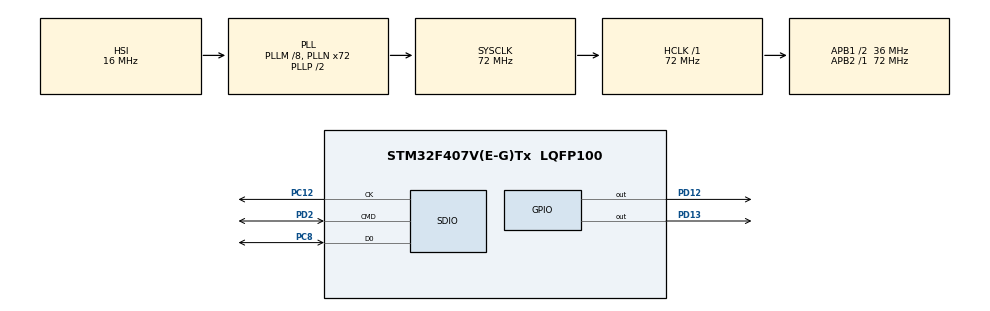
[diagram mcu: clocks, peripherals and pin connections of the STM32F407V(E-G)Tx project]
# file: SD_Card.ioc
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FATFS._MAX_SS=4096
Mcu.Family=STM32F4
Mcu.Name=STM32F407V(E-G)Tx
Mcu.Package=LQFP100
NVIC.PriorityGroup=NVIC_PRIORITYGROUP_0
PC12.Mode=SD_1_bit
PC12.Signal=SDIO_CK
PC8.Mode=SD_1_bit
PC8.Signal=SDIO_D0
PD12.Signal=GPIO_Output
PD13.Signal=GPIO_Output
PD2.Mode=SD_1_bit
PD2.Signal=SDIO_CMD
ProjectManager.HeapSize=0x200
ProjectManager.StackSize=0x400
ProjectManager.TargetToolchain=STM32CubeIDE
RCC.48MHZClocksFreq_Value=48000000
RCC.AHBFreq_Value=72000000
RCC.APB1CLKDivider=RCC_HCLK_DIV2
RCC.APB1Freq_Value=36000000
RCC.APB1TimFreq_Value=72000000
RCC.APB2Freq_Value=72000000
RCC.APB2TimFreq_Value=72000000
RCC.CortexFreq_Value=72000000
RCC.HCLKFreq_Value=72000000
RCC.HSE_VALUE=8000000
RCC.HSI_VALUE=16000000
RCC.PLLM=8
RCC.PLLN=72
RCC.PLLQ=3
RCC.SYSCLKFreq_VALUE=72000000
RCC.SYSCLKSource=RCC_SYSCLKSOURCE_PLLCLK
RCC.VCOOutputFreq_Value=144000000
SDIO.ClockDiv=3
VP_FATFS_VS_SDIO.Mode=SDIO
board=STM32F407G-DISC1

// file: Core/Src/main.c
/* USER CODE BEGIN Header */
/**
  ******************************************************************************
  * @file           : main.c
  * @brief          : Main program body
  ******************************************************************************
  * @attention
  *
  * Copyright (c) 2024 STMicroelectronics.
  * All rights reserved.
  *
  * This software is licensed under terms that can be found in the LICENSE file
  * in the root directory of this software component.
  * If no LICENSE file comes with this software, it is provided AS-IS.
  *
  ******************************************************************************
  */
/* USER CODE END Header */
#include "main.h"
#include "fatfs.h"

SD_HandleTypeDef hsd;

void SystemClock_Config(void);
static void MX_GPIO_Init(void);
static void MX_SDIO_SD_Init(void);

int main(void)
{

  /* MCU Configuration--------------------------------------------------------*/

  /* Reset of all peripherals, Initializes the Flash interface and the Systick. */
  HAL_Init();

  /* Configure the system clock */
  SystemClock_Config();

  /* Initialize all configured peripherals */
  MX_GPIO_Init();
  MX_SDIO_SD_Init();
  MX_FATFS_Init();
  /* USER CODE BEGIN 2 */

  FATFS my_fatfs;
  FIL my_file;
  UINT testbyte;

  if( f_mount(&my_fatfs, SDPath, 1) == FR_OK){

	  HAL_GPIO_WritePin(GPIOD, GPIO_PIN_13, GPIO_PIN_SET);
	  char my_path[] = "WRITE1.TXT";
	  f_open(&my_file, my_path, FA_WRITE | FA_CREATE_ALWAYS);
	  uint8_t my_data[] = "Hello guys my name is citak and u are in Ç the citakworks place!";
	  f_write(&my_file, my_data, sizeof(my_data), &testbyte);
	  f_close(&my_file);
	  HAL_Delay(50);
	  HAL_GPIO_WritePin(GPIOD, GPIO_PIN_12, GPIO_PIN_SET);
  }

  /* USER CODE END 2 */

  /* Infinite loop */
  while (1)
  {

  }
}

void SystemClock_Config(void)
{
  RCC_OscInitTypeDef RCC_OscInitStruct = {0};
  RCC_ClkInitTypeDef RCC_ClkInitStruct = {0};

  /** Configure the main internal regulator output voltage
  */
  __HAL_RCC_PWR_CLK_ENABLE();
  __HAL_PWR_VOLTAGESCALING_CONFIG(PWR_REGULATOR_VOLTAGE_SCALE1);

  /** Initializes the RCC Oscillators according to the specified parameters
  * in the RCC_OscInitTypeDef structure.
  */
  RCC_OscInitStruct.OscillatorType = RCC_OSCILLATORTYPE_HSI;
  RCC_OscInitStruct.HSIState = RCC_HSI_ON;
  RCC_OscInitStruct.HSICalibrationValue = RCC_HSICALIBRATION_DEFAULT;
  RCC_OscInitStruct.PLL.PLLState = RCC_PLL_ON;
  RCC_OscInitStruct.PLL.PLLSource = RCC_PLLSOURCE_HSI;
  RCC_OscInitStruct.PLL.PLLM = 8;
  RCC_OscInitStruct.PLL.PLLN = 72;
  RCC_OscInitStruct.PLL.PLLP = RCC_PLLP_DIV2;
  RCC_OscInitStruct.PLL.PLLQ = 3;
  if (HAL_RCC_OscConfig(&RCC_OscInitStruct) != HAL_OK)
  {
    Error_Handler();
  }

  /** Initializes the CPU, AHB and APB buses clocks
  */
  RCC_ClkInitStruct.ClockType = RCC_CLOCKTYPE_HCLK|RCC_CLOCKTYPE_SYSCLK
                              |RCC_CLOCKTYPE_PCLK1|RCC_CLOCKTYPE_PCLK2;
  RCC_ClkInitStruct.SYSCLKSource = RCC_SYSCLKSOURCE_PLLCLK;
  RCC_ClkInitStruct.AHBCLKDivider = RCC_SYSCLK_DIV1;
  RCC_ClkInitStruct.APB1CLKDivider = RCC_HCLK_DIV2;
  RCC_ClkInitStruct.APB2CLKDivider = RCC_HCLK_DIV1;

  if (HAL_RCC_ClockConfig(&RCC_ClkInitStruct, FLASH_LATENCY_2) != HAL_OK)
  {
    Error_Handler();
  }
}

static void MX_SDIO_SD_Init(void)
{

  hsd.Instance = SDIO;
  hsd.Init.ClockEdge = SDIO_CLOCK_EDGE_RISING;
  hsd.Init.ClockBypass = SDIO_CLOCK_BYPASS_DISABLE;
  hsd.Init.ClockPowerSave = SDIO_CLOCK_POWER_SAVE_DISABLE;
  hsd.Init.BusWide = SDIO_BUS_WIDE_1B;
  hsd.Init.HardwareFlowControl = SDIO_HARDWARE_FLOW_CONTROL_DISABLE;
  hsd.Init.ClockDiv = 3;

}

static void MX_GPIO_Init(void)
{
  GPIO_InitTypeDef GPIO_InitStruct = {0};

  /* GPIO Ports Clock Enable */
  __HAL_RCC_GPIOD_CLK_ENABLE();
  __HAL_RCC_GPIOC_CLK_ENABLE();

  /*Configure GPIO pin Output Level */
  HAL_GPIO_WritePin(GPIOD, GPIO_PIN_12|GPIO_PIN_13, GPIO_PIN_RESET);

  /*Configure GPIO pins : PD12 PD13 */
  GPIO_InitStruct.Pin = GPIO_PIN_12|GPIO_PIN_13;
  GPIO_InitStruct.Mode = GPIO_MODE_OUTPUT_PP;
  GPIO_InitStruct.Pull = GPIO_NOPULL;
  GPIO_InitStruct.Speed = GPIO_SPEED_FREQ_LOW;
  HAL_GPIO_Init(GPIOD, &GPIO_InitStruct);

}

void Error_Handler(void)
{
  __disable_irq();
  while (1)
  {
  }
}
